# SAM9X60 device description
Architecture: ARM926EJS; Family: SAM9; Series: SAM9X
Registers are 32-bit, read-write, no defined reset value unless marked. A register's access mark holds for its fields unless they carry their own. Offsets are from the block's base; [hi:lo] are bit positions.

## SFR — Special Function Registers
Instances: SFR 0xF8050000
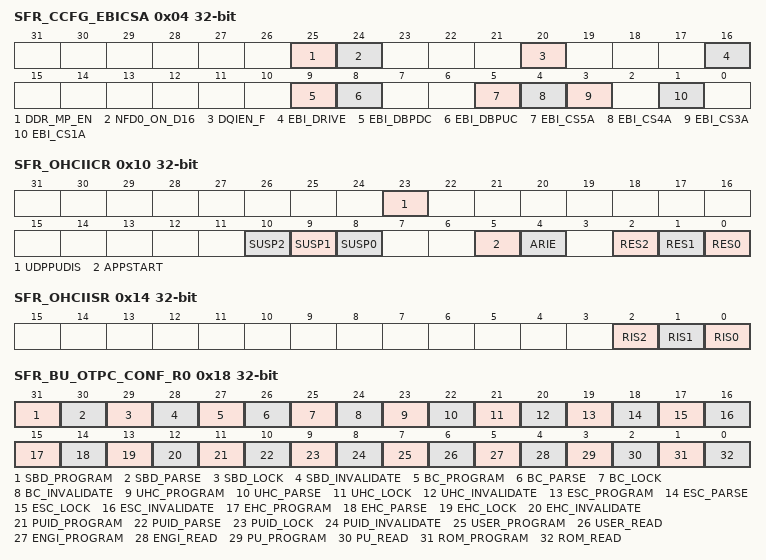
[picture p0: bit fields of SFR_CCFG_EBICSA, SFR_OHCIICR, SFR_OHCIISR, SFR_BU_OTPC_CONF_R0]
0x04 SFR_CCFG_EBICSA — EBI Chip Select Register
  [25] DDR_MP_EN — DDR Multi-port Enable
  [24] NFD0_ON_D16 — NAND Flash Databus Selection
  [20] DQIEN_F — Force Analog Input Comparator Configuration
  [16] EBI_DRIVE — EBI I/O Drive Configuration
  [9] EBI_DBPDC — EBI Data Bus Pulldown Configuration
  [8] EBI_DBPUC — EBI Data Bus Pullup Configuration
  [5] EBI_CS5A — EBI Chip Select 5 Assignment
  [4] EBI_CS4A — EBI Chip Select 4 Assignment
  [3] EBI_CS3A — EBI Chip Select 3 Assignment
  [1] EBI_CS1A — EBI Chip Select 1 Assignment
0x10 SFR_OHCIICR — OHCI Interrupt Configuration Register
  [23] UDPPUDIS — USB Device Pullup Disable
  [10] SUSP2 — USB PORTx
  [9] SUSP1 — USB PORTx
  [8] SUSP0 — USB PORTx
  [5] APPSTART — OHCI Clock Start
  [4] ARIE — OHCI Asynchronous Resume Interrupt Enable
  [2] RES2 — USB PORTx Reset
  [1] RES1 — USB PORTx Reset
  [0] RES0 — USB PORTx Reset
0x14 SFR_OHCIISR ro — OHCI Interrupt Status Register
  [2] RIS2 — OHCI Resume Interrupt Status Port 2
  [1] RIS1 — OHCI Resume Interrupt Status Port 1
  [0] RIS0 — OHCI Resume Interrupt Status Port 0
0x18 SFR_BU_OTPC_CONF_R0 — OTPC Configuration 0 Register (BackUp)
  [31] SBD_PROGRAM — Programming of User Secure Boot Configuration Special Packet
    0=ENABLE (Enables programming of the User Secure Boot Configuration special packet.); 1=DISABLE (Disables programming of the User Secure Boot Configuration special packet.)
  [30] SBD_PARSE — Parsing of User Secure Boot Configuration Special Packet
    0=ENABLE (Enables parsing of the User Secure Boot Configuration special packet.); 1=DISABLE (Disables parsing of the User Secure Boot Configuration special packet.)
  [29] SBD_LOCK — Lock of User Secure Boot Configuration Special Packet
    0=ENABLE (Enables lock of the User Secure Boot Configuration special packet.); 1=DISABLE (Disables lock of the User Secure Boot Configuration special packet.)
  [28] SBD_INVALIDATE — Invalidation of User Secure Boot Configuration Special Packet
    0=ENABLE (Enables invalidation of the User Secure Boot Configuration special packet.); 1=DISABLE (Disables invalidation of the User Secure Boot Configuration special packet.)
  [27] BC_PROGRAM — Programming of User Boot Configuration Special Packet
    0=ENABLE (Enables programming of the User Boot Configuration special packet.); 1=DISABLE (Disables programming of the User Boot Configuration special packet.)
  [26] BC_PARSE — Parsing of User Boot Configuration Special Packet
    0=ENABLE (Enables parsing of the User Boot Configuration special packet.); 1=DISABLE (Disables parsing of the User Boot Configuration special packet.)
  [25] BC_LOCK — Lock of User Boot Configuration Special Packet
    0=ENABLE (Enables lock of the User Boot Configuration special packet.); 1=DISABLE (Disables lock of the User Boot Configuration special packet.)
  [24] BC_INVALIDATE — Invalidation of User Boot Configuration Special Packet
    0=ENABLE (Enables invalidation of the User Boot Configuration special packet.); 1=DISABLE (Disables invalidation of the User Boot Configuration special packet.)
  [23] UHC_PROGRAM — Programming of User Hardware Configuration Special Packet
    0=ENABLE (Enables programming of the User Hardware Configuration special packet.); 1=DISABLE (Disables programming of the User Hardware Configuration special packet.)
  [22] UHC_PARSE — Parsing of User Hardware Configuration Special Packet
    0=ENABLE (Enables parsing of the User Hardware Configuration special packet.); 1=DISABLE (Disables parsing of the User Hardware Configuration special packet.)
  [21] UHC_LOCK — Lock of User Hardware Configuration Special Packet
    0=ENABLE (Enables lock of the User Hardware Configuration special packet.); 1=DISABLE (Disables lock of the User Hardware Configuration special packet.)
  [20] UHC_INVALIDATE — Invalidation of User Hardware Configuration Special Packet
    0=ENABLE (Enables invalidation of the User Hardware Configuration special packet.); 1=DISABLE (Disables invalidation of the User Hardware Configuration special packet.)
  [19] ESC_PROGRAM — Programming of Engineering Security Configuration Special Packet
    0=ENABLE (Enables programming of the Engineering Security Configuration special packet.); 1=DISABLE (Disables programming of the Engineering Security Configuration special packet.)
  [18] ESC_PARSE — Parsing of Engineering Security Configuration Special Packet
    0=ENABLE (Enables parsing of the Engineering Security Configuration special packet.); 1=DISABLE (Disables parsing of the Engineering Security Configuration special packet.)
  [17] ESC_LOCK — Lock of Engineering Security Configuration Special Packet
    0=ENABLE (Enables lock of the Engineering Security Configuration special packet.); 1=DISABLE (Disables lock of the Engineering Security Configuration special packet.)
  [16] ESC_INVALIDATE — Invalidation of Engineering Security Configuration Special Packet
    0=ENABLE (Enables invalidation of the Engineering Security Configuration special packet.); 1=DISABLE (Disables invalidation of the Engineering Security Configuration special packet.)
  [15] EHC_PROGRAM — Programming of Engineering Hardware Configuration Special Packet
    0=ENABLE (Enables programming of the Engineering Hardware Configuration special packet.); 1=DISABLE (Disables programming of the Engineering Hardware Configuration special packet.)
  [14] EHC_PARSE — Parsing of Engineering Hardware Configuration Special Packet
    0=ENABLE (Enables parsing of the Engineering Hardware Configuration special packet.); 1=DISABLE (Disables parsing of the Engineering Hardware Configuration special packet.)
  [13] EHC_LOCK — Lock of Engineering Hardware Configuration Special Packet
    0=ENABLE (Enables lock of the Engineering Hardware Configuration special packet.); 1=DISABLE (Disables lock of the Engineering Hardware Configuration special packet.)
  [12] EHC_INVALIDATE — Invalidation of Engineering Hardware Configuration Special Packet
    0=ENABLE (Enables invalidation of the Engineering Hardware Configuration special packet.); 1=DISABLE (Disables invalidation of the Engineering Hardware Configuration special packet.)
  [11] PUID_PROGRAM — Programming of Product UID Special Packet
    0=ENABLE (Enables programming of the Product UID special packet.); 1=DISABLE (Disables programming of the Product UID special packet.)
  [10] PUID_PARSE — Parsing of Product UID Special Packet
    0=ENABLE (Enables parsing of the Product UID special packet.); 1=DISABLE (Disables parsing of the Product UID special packet.)
  [9] PUID_LOCK — Lock of Product UID Special Packet
    0=ENABLE (Enables lock of the Product UID special packet.); 1=DISABLE (Disables lock of the Product UID special packet.)
  [8] PUID_INVALIDATE — Invalidation of Product UID Special Packet
    0=ENABLE (Enables invalidation of the Product UID special packet.); 1=DISABLE (Disables invalidation of the Product UID special packet.)
  [7] USER_PROGRAM — Programming of User Area
    0=ENABLE (Enables programming of the user area.); 1=DISABLE (Disables programming of the user area.)
  [6] USER_READ — Reading of User Area
    0=ENABLE (Enables reading of the user area.); 1=DISABLE (Disables reading of the user area.)
  [5] ENGI_PROGRAM — Programming of Engineering Area
    0=ENABLE (Enables programming of the engineering area.); 1=DISABLE (Disables programming of the engineering area.)
  [4] ENGI_READ — Reading of Engineering Area
    0=ENABLE (Enables reading of the engineering area.); 1=DISABLE (Disables reading of the engineering area.)
  [3] PU_PROGRAM — Programming of Patch Unit
    0=ENABLE (Enables programming of the patch unit.); 1=DISABLE (Disables programming of the patch unit.)
  [2] PU_READ — Reading of Patch Unit
    0=ENABLE (Enables reading of the patch unit.); 1=DISABLE (Disables reading of the patch unit.)
  [1] ROM_PROGRAM — Programming of ROM (OTP part only)
    0=ENABLE (Enables programming of the ROM (OTP part only).); 1=DISABLE (Disables programming of the ROM (OTP part only).)
  [0] ROM_READ — Reading of ROM (OTP part only)
    0=ENABLE (Enables reading of the ROM (OTP part only).); 1=DISABLE (Disables reading of the ROM (OTP part only).)
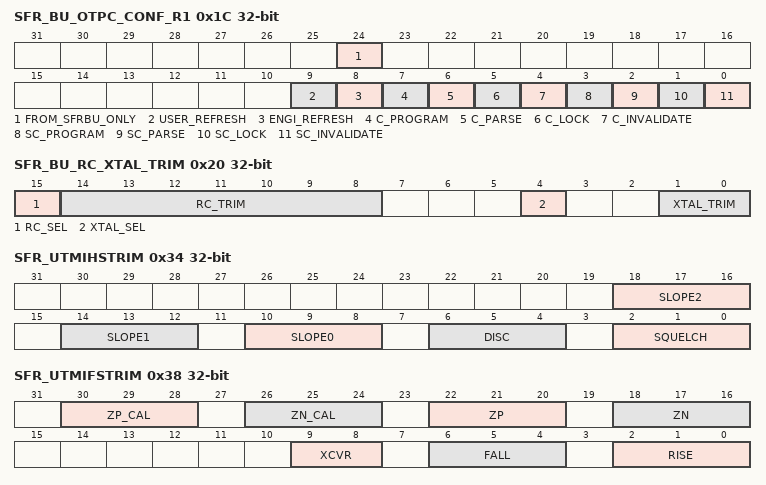
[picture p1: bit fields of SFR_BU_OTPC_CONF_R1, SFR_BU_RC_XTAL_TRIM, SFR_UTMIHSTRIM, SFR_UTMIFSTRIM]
0x1C SFR_BU_OTPC_CONF_R1 — OTPC Configuration 1 Register (BackUp)
  [24] FROM_SFRBU_ONLY — OTPC Configuration Signal
  [9] USER_REFRESH — User Area Refresh
    0=ALLOWED (Allows refresh of the User Area.); 1=FORBIDDEN (Forbids refresh of the User Area.)
  [8] ENGI_REFRESH — Engineering Area Refresh
    0=ALLOWED (Allows refresh of the Engineering Area.); 1=FORBIDDEN (Forbids refresh of the Engineering Area.)
  [7] C_PROGRAM — Programming of User Custom Special Packet (Non-Secure World)
    0=ENABLE (Enables programming of the User Custom special packet (for Non-Secure World).); 1=DISABLE (Disables programming of the User Custom special packet (for Non-Secure World).)
  [6] C_PARSE — Parsing of User Custom Special Packet (Non-Secure World)
    0=ENABLE (Enables parsing of the User Custom special packet (for Non-Secure World).); 1=DISABLE (Disables parsing of the User Custom special packet (for Non-Secure World).)
  [5] C_LOCK — Lock of User Custom Special Packet (Non-Secure World)
    0=ENABLE (Enables lock of the User Custom special packet (for Non-Secure World).); 1=DISABLE (Disables lock of the User Custom special packet (for Non-Secure World).)
  [4] C_INVALIDATE — Invalidation of User Custom Special Packet (Non-Secure World)
    0=ENABLE (Enables invalidation of the User Custom special packet (for Non-Secure World).); 1=DISABLE (Disables invalidation of the User Custom special packet (for Non-Secure World).)
  [3] SC_PROGRAM — Programming of User Custom Special Packet (Secure World)
    0=ENABLE (Enables programming of the User Custom special packet (for Secure World).); 1=DISABLE (Disables programming of the User Custom special packet (for Secure World).)
  [2] SC_PARSE — Parsing of the User Custom Special Packet (Secure World)
    0=ENABLE (Enables parsing of the User Custom special packet (for Secure World).); 1=DISABLE (Disables parsing of the User Custom special packet (for Secure World).)
  [1] SC_LOCK — Lock of User Custom Special Packet (Secure World)
    0=ENABLE (Enables lock of the User Custom special packet (for Secure World).); 1=DISABLE (Disables lock of the User Custom special packet (for Secure World).)
  [0] SC_INVALIDATE — Invalidation of User Custom Special Packet (Secure World)
    0=ENABLE (Enables invalidation of the User Custom special packet (for Secure World).); 1=DISABLE (Disables invalidation of the User Custom special packet (for Secure World).)
0x20 SFR_BU_RC_XTAL_TRIM — RC and XTAL Oscillator Trimming Register (BackUp)
  [15] RC_SEL — 32 kHz RC Oscillator Trimming Select
  [14:8] RC_TRIM — 32 kHz RC Oscillator Trimming Value
  [4] XTAL_SEL — 32.768 kHz Crystal Oscillator Trimming Select
  [1:0] XTAL_TRIM — 32.768 kHz Crystal Oscillator Trimming Value
0x30 SFR_UTMICKTRIM — UTMI Clock Trimming Register
  [17:16] VBG — UTMI Band Gap Voltage Trimming
0x34 SFR_UTMIHSTRIM — UTMI High-Speed Trimming Register
  [18:16] SLOPE2 — UTMI HS PORTx Transceiver Slope Trimming
  [14:12] SLOPE1 — UTMI HS PORTx Transceiver Slope Trimming
  [10:8] SLOPE0 — UTMI HS PORTx Transceiver Slope Trimming
  [6:4] DISC — UTMI Disconnect Voltage Trimming
  [2:0] SQUELCH — UTMI HS Squelch Voltage Trimming
0x38 SFR_UTMIFSTRIM — UTMI Full-Speed Trimming Register
  [30:28] ZP_CAL — FS Transceiver PMOS Impedance Calibration
  [26:24] ZN_CAL — FS Transceiver NMOS Impedance Calibration
  [22:20] ZP — FS Transceiver PMOS Impedance Trimming
  [18:16] ZN — FS Transceiver NMOS Impedance Trimming
  [9:8] XCVR — FS Transceiver Crossover Voltage Trimming
  [6:4] FALL — FS Transceiver Output Falling Slope Trimming
  [2:0] RISE — FS Transceiver Output Rising Slope Trimming
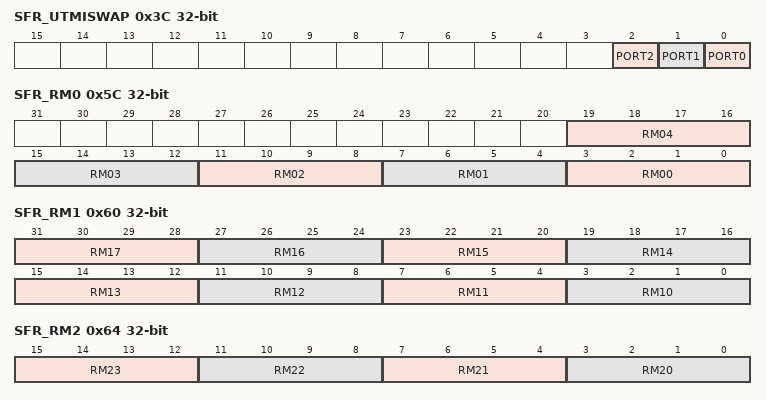
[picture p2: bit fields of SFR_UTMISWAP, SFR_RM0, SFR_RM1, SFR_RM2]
0x3C SFR_UTMISWAP — UTMI DP/DM Pin Swapping Register
  [all] fields
    0=NORMAL (DP/DM normal pinout.); 1=SWAPPED (DP/DM swapped pinout.)
  [2] PORT2 — PORT 2 DP/DM Pin Swapping
  [1] PORT1 — PORT 1 DP/DM Pin Swapping
  [0] PORT0 — PORT 0 DP/DM Pin Swapping
0x5C SFR_RM0 — Read Margin0 Register
  [19:16] RM04 — WRITE_MARGIN Value: i_queue_rf2p - 68 bytes (rf2p) - gfx2d_queue_rf2p_dc_8x68 (GFX2D)
  [15:12] RM03 — READ_MARGIN Value: i_queue_rf2p - 68 bytes (rf2p) - gfx2d_queue_rf2p_dc_8x68 (GFX2D)
  [11:8] RM02 — READ_MARGIN Value: i_clut_rf1p - 2 Kbytes (rf1p) - gfx2d_clut_rf_sc_512x32 (GFX2D)
  [7:4] RM01 — WRITE_MARGIN Value: i_bank0_msb_rf2p, i_bank0_lsb_rf2p, i_bank1_msb_rf2p, i_bank1_lsb_rf2p - 512 bytes (rf2p) - gfx2d_bank_rf2p_dc_32x32sw1 (GFX2D)
  [3:0] RM00 — READ_MARGIN Value: i_bank0_msb_rf2p, i_bank0_lsb_rf2p, i_bank1_msb_rf2p, i_bank1_lsb_rf2p - 512 bytes (rf2p) - gfx2d_bank_rf2p_dc_32x32sw1 (GFX2D)
0x60 SFR_RM1 — Read Margin1 Register
  [31:28] RM17 — READ_MARGIN Value: i_lcd_heo_cue0, i_lcd_heo_cue1 - 2 Kbytes (rf1p) - hlcdc_heocue_rf_sc_512x16sw1 (HLCDC5)
  [27:24] RM16 — READ_MARGIN Value: i_lcd_ovr1_sram, i_lcd_ovr2_sram - 2 Kbytes (sram) hlcdc_ovr_sram_256x32sw1 (HLCDC5)
  [23:20] RM15 — READ_MARGIN Value: i_lcd_heo_scaler0, i_lcd_heo_scaler1, i_lcd_heo_scaler2 - 3 Kbytes (sram) hlcdc_heoscaler_sram_1024x24sw1 (HLCDC5)
  [19:16] RM14 — WRITE_MARGIN Value: i_lcd_output_fifo - 1.5 Kbytes (rf2p) - hlcdc_fifo_rf2p_dc_512x24 (HLCDC5)
  [15:12] RM13 — READ_MARGIN Value: i_lcd_output_fifo - 1.5 Kbytes (rf2p) - hlcdc_fifo_rf2p_dc_512x24 (HLCDC5)
  [11:8] RM12 — WRITE_MARGIN Value: i_lcd_base_fifo, i_lcd_ovr1_rf2p, i_lcd_ovr2_rf2p, i_lcd_heo_fifo, i_lcd_heop1_fifo, i_lcd_heop2_fifo - 816 bytes (rf2p) - hlcdc_fifo_rf2p_dc_32x34 (HLCDC5)
  [7:4] RM11 — READ_MARGIN Value: i_lcd_base_fifo, i_lcd_ovr1_rf2p, i_lcd_ovr2_rf2p, i_lcd_heo_fifo, i_lcd_heop1_fifo, i_lcd_heop2_fifo - 816 bytes (rf2p) - hlcdc_fifo_rf2p_dc_32x34 (HLCDC5)
  [3:0] RM10 — READ_MARGIN Value: i_lcd_base_clut, i_lcd_heo_clut - 2 Kbytes (rf1p) - hlcdc_clut_rf_sc_256x32sw1 (HLCDC5)
0x64 SFR_RM2 — Read Margin2 Register
  [15:12] RM23 — READ-WRITE_MARGIN Value Port B: i_husb2dev_dpram_4112x32 - 16.5 Kbytes (dpsram) husb2dev_dpram_4224x32sw1 (HUSB)
  [11:8] RM22 — READ-WRITE_MARGIN Value Port A: i_husb2dev_dpram_4112x32 - 16.5 Kbytes (dpsram) husb2dev_dpram_4224x32sw1 (HUSB)
  [7:4] RM21 — READ-WRITE_MARGIN Value Port B SDMMC0.i_dpram, SDMMC1.i_dpram - 2 Kbytes (dpsram) sdmmc_dpram_256x32sw1 (SDMMC)
  [3:0] RM20 — READ-WRITE_MARGIN Value Port A: SDMMC0.i_dpram, SDMMC1.i_dpram - 2 Kbytes (dpsram) sdmmc_dpram_256x32sw1 (SDMMC)
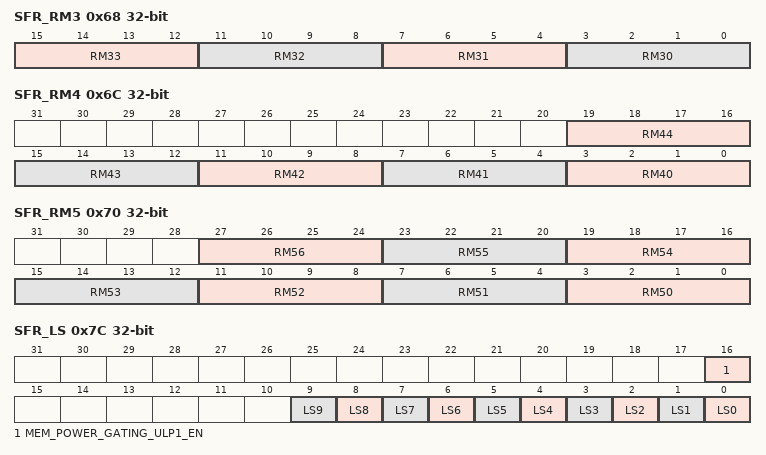
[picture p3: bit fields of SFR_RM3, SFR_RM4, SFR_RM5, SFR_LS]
0x68 SFR_RM3 — Read Margin3 Register
  [15:12] RM33 — READ-WRITE_MARGIN Value: i_descram- 320 bytes (rf1p) - uhp_rf_sc_80x32 (EHCI/OHCI)
  [11:8] RM32 — READ-WRITE_MARGIN Value: i_daram - 4 Kbytes (rf1p) - uhp_rf_sc_512x64 (EHCI/OHCI)
  [7:4] RM31 — READ-WRITE_MARGIN Value Port B: i_dpram_1056x32 - 4.125 Kbytes (dpsram) hxdma_dpram_1056x32sw1 (HXDMA)
  [3:0] RM30 — READ-WRITE_MARGIN Value Port A: i_dpram_1056x32 - 4.125 Kbytes (dpsram) hxdma_dpram_1056x32sw1 (HXDMA)
0x6C SFR_RM4 — Read Margin4 Register
  [19:16] RM44 — READ-WRITE_MARGIN Value: i_otpc_rf_sc_264x32sw1 - 1 Kbyte (rf1p) - otpc_rf_sc_264x32sw1 (OTPC)
  [15:12] RM43 — READ_MARGIN Value: i_rom_24576x32_ecc - 96 Kbytes - (rom) - rom_system_rom_24576x32 (ROM)
  [11:8] RM42 — READ_MARGIN Value: i_rom_16384x32_sys - 64 Kbytes - (rom) - rom_system_rom_16384x32 (ROM)
  [7:4] RM41 — READ-WRITE_MARGIN Value: i_ahb_sram_otpc - 4 Kbytes (sram) - otpc_sram_1024x32sw1 (SRAM1 (OTPC))
  [3:0] RM40 — READ-WRITE_MARGIN Value: i_ahb_sram - 64 Kbytes (sram) - system_sram_16384x32sw1 (SRAM0)
0x70 SFR_RM5 — Read Margin5 Register
  [27:24] RM56 — READ-WRITE_MARGIN Value: uICDataRam0, uICDataRam1, uICDataRam2, uICDataRam3,- 32 Kbytes (sram) - sram_2048x32 (ARM926). uDCDataRam0, uDCDataRam1, uDCDataRam2, uDCDataRam3 - 32 Kbytes (sram) - sram_2048x32sw1 (ARM926)
  [23:20] RM55 — READ-WRITE_MARGIN Value: uMMU0, uMMU2 - 208 bytes (rf1p) - rf_32x26 (ARM926)
  [19:16] RM54 — READ-WRITE_MARGIN Value: uMMU1, uMMU3 - 240 bytes (rf1p) - rf_32x30 (ARM926)
  [15:12] RM53 — READ_MARGIN Value: uDCDirtyRam - 256 bytes (rf1p) - rf_256x8 (ARM926)
  [11:8] RM52 — READ_MARGIN Value: uDCTagRam0, uDCTagRam1, uDCTagRam2, uDCTagRam3 - 5.5 Kbytes (rf1p) - rf_512x22 (ARM926)
  [7:4] RM51 — READ-WRITE_MARGIN Value: uICValidRam, uDCValidRam - 384 bytes (rf1p) - rf_64x24 (ARM926)
  [3:0] RM50 — READ-WRITE_MARGIN Value: uICTagRam0, uICTagRam1, uICTagRam2, uICTagRam3 - 2.75 Kbytes (rf1p) - rf_256x22 (ARM926)
0x7C SFR_LS — Light Sleep Register
  [16] MEM_POWER_GATING_ULP1_EN — Light Sleep Value for ULP1 Power-Gated Memories
  [9] LS9 — Light Sleep Value (ARM926)
  [8] LS8 — Light Sleep Value (ROM + OTPC) (This bit is used by rom_16384x32_sys, rom_24576x32_ecc and otpc_rf_sc_264x32sw1)
  [7] LS7 — Light Sleep Value (SRAM1 (OTPC)) (This bit is used by i_ahb_sram_otpc)
  [6] LS6 — Light Sleep Value (SRAM0)
  [5] LS5 — Light Sleep Value (EHCI/OHCI)
  [4] LS4 — Light Sleep Value (HXDMA)
  [3] LS3 — Light Sleep Value (HUSB)
  [2] LS2 — Light Sleep Value (SDMMC)
  [1] LS1 — Light Sleep Value (HLCDC5)
  [0] LS0 — Light Sleep Value (GFX2D)
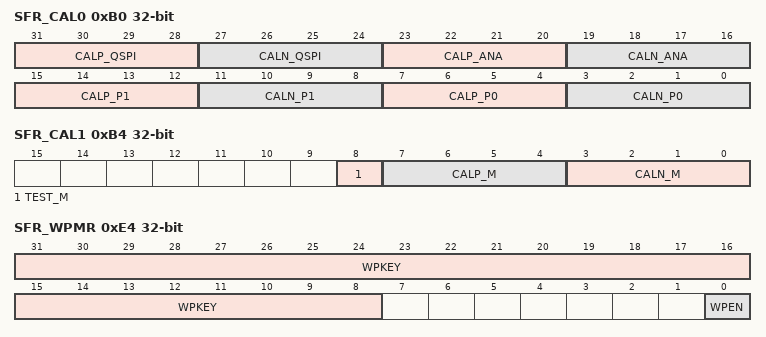
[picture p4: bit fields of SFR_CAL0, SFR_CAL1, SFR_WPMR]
0xB0 SFR_CAL0 — I/O Calibration 0 Register
  [31:28] CALP_QSPI — Calibration of High Level Output Impedance of Pads with VDDQSPI Supply
  [27:24] CALN_QSPI — Calibration of Low Level Output Impedance of Pads with VDDQSPI Supply
  [23:20] CALP_ANA — Calibration of High Level Output Impedance of Pads with VDDANA Supply
  [19:16] CALN_ANA — Calibration of Low Level Output Impedance of Pads with VDDANA Supply
  [15:12] CALP_P1 — Calibration of High Level Output Impedance of Pads with VDDIOP1 Supply
  [11:8] CALN_P1 — Calibration of Low Level Output Impedance of Pads with VDDIOP1 Supply
  [7:4] CALP_P0 — Calibration of High Level Output Impedance of Pads with VDDIOP0 Supply
  [3:0] CALN_P0 — Calibration of Low Level Output Impedance of Pads with VDDIOP0 Supply
0xB4 SFR_CAL1 — I/O Calibration 1 Register
  [8] TEST_M — Enable Calibration of Low/High Level Output Impedance of Pads with VDDIOM Supply
  [7:4] CALP_M — Calibration of High Level Output Impedance of Pads with VDDIOM Supply
  [3:0] CALN_M — Calibration of Low Level Output Impedance of Pads with VDDIOM Supply
0xE4 SFR_WPMR — Write Protection Mode Register
  [31:8] WPKEY — Write Protection Key
    0x534652=PASSWD (Writing any other value in this field aborts the write operation of the WPEN bit. Always reads as 0.)
  [0] WPEN — Write Protection Enable
0x100 SFR_SPARE — Spare Register
  [31:0] VALUE — Spare
0x104 SFR_BU_SPARE — Spare Register (BackUp)
  [15:0] VALUE — Spare
